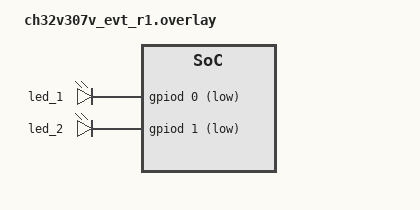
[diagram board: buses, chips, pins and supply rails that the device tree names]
/* SPDX-License-Identifier: Apache-2.0 */

/ {
	aliases {
		led0 = &led_1;
		led1 = &led_2;
	};

	leds {
		compatible = "gpio-leds";

		led_1: led1 {
			gpios = <&gpiod 0 GPIO_ACTIVE_LOW>;
		};

		led_2: led2 {
			gpios = <&gpiod 1 GPIO_ACTIVE_LOW>;
		};
	};
};
